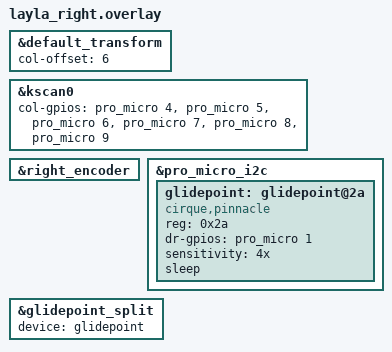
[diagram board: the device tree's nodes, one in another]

#include "layla.dtsi"

&default_transform {
	col-offset = <6>;
};

&kscan0 {
    col-gpios
        = <&pro_micro 4 GPIO_ACTIVE_HIGH>
        , <&pro_micro 5 GPIO_ACTIVE_HIGH>
        , <&pro_micro 6 GPIO_ACTIVE_HIGH>
        , <&pro_micro 7 GPIO_ACTIVE_HIGH>
        , <&pro_micro 8 GPIO_ACTIVE_HIGH>
        , <&pro_micro 9 GPIO_ACTIVE_HIGH>
        ;
};

&right_encoder {
    status = "okay";
};


&pro_micro_i2c {
    status = "okay";
	
    glidepoint: glidepoint@2a {
        compatible = "cirque,pinnacle";
        reg = <0x2a>;
        status = "okay";
        dr-gpios = <&pro_micro 1 (GPIO_ACTIVE_HIGH)>; // DR pin on cirque is always &vik_conn 5

        sensitivity = "4x";
        sleep;
    };
};

&glidepoint_split {
    device = <&glidepoint>;
};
